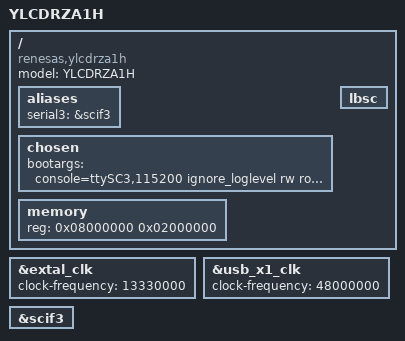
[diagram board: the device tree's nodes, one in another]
/*
 * Device Tree Source for the YLCDRZA1H board
 *
 * Copyright (C) 2017 Renesas America
 *
 * This file is licensed under the terms of the GNU General Public License
 * version 2.  This program is licensed "as is" without any warranty of any
 * kind, whether express or implied.
 */

/dts-v1/;
#include "r7s72100.dtsi"

/ {
	model = "YLCDRZA1H";
	compatible = "renesas,ylcdrza1h", "renesas,r7s72100";

	aliases {
		serial3 = &scif3;
	};

	chosen {
		/* Add lots of white space so we have room to overwirte in u-boot */
		bootargs = "console=ttySC3,115200 ignore_loglevel rw root=/dev/nfs ip=dhcp\
                                                                                       ";

	};

	memory {
		device_type = "memory";
		reg = <0x08000000 0x02000000>;	/* 32MB @ 0x0x08000000 */
	};

	lbsc {
		#address-cells = <1>;
		#size-cells = <1>;
	};
};

&extal_clk {
	clock-frequency = <13330000>;
};

&usb_x1_clk {
	clock-frequency = <48000000>;
};

&scif3 {
	status = "okay";
};
